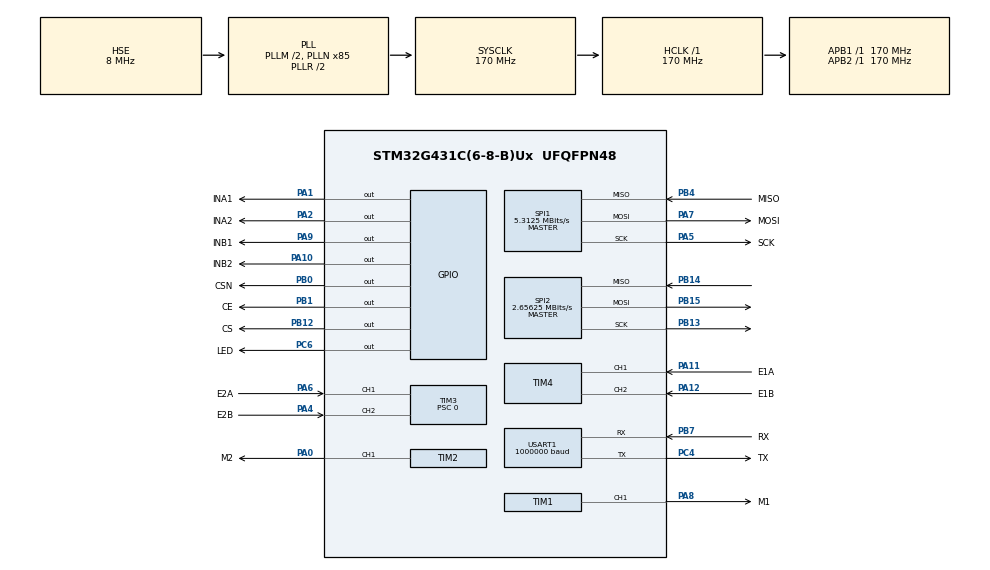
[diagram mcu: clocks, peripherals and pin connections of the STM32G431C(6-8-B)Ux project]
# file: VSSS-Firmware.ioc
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Mcu.Family=STM32G4
Mcu.Name=STM32G431C(6-8-B)Ux
Mcu.Package=UFQFPN48
NVIC.PriorityGroup=NVIC_PRIORITYGROUP_4
PA0.GPIO_Label=M2
PA0.Signal=S_TIM2_CH1
PA1.GPIO_Label=INA1
PA1.Signal=GPIO_Output
PA10.GPIO_Label=INB2
PA10.Signal=GPIO_Output
PA11.GPIO_Label=E1A
PA11.Signal=S_TIM4_CH1
PA12.GPIO_Label=E1B
PA12.Signal=S_TIM4_CH2
PA2.GPIO_Label=INA2
PA2.Signal=GPIO_Output
PA4.GPIO_Label=E2B
PA4.Signal=S_TIM3_CH2
PA5.GPIO_Label=SCK
PA5.Mode=Full_Duplex_Master
PA5.Signal=SPI1_SCK
PA6.GPIO_Label=E2A
PA6.Signal=S_TIM3_CH1
PA7.GPIO_Label=MOSI
PA7.Mode=Full_Duplex_Master
PA7.Signal=SPI1_MOSI
PA8.GPIO_Label=M1
PA8.GPIO_Speed=GPIO_SPEED_FREQ_HIGH
PA8.Signal=S_TIM1_CH1
PA9.GPIO_Label=INB1
PA9.Signal=GPIO_Output
PB0.GPIO_Label=CSN
PB0.Signal=GPIO_Output
PB1.GPIO_Label=CE
PB1.Signal=GPIO_Output
PB12.GPIO_Label=CS
PB12.Signal=GPIO_Output
PB13.Mode=Full_Duplex_Master
PB13.Signal=SPI2_SCK
PB14.Mode=Full_Duplex_Master
PB14.Signal=SPI2_MISO
PB15.Mode=Full_Duplex_Master
PB15.Signal=SPI2_MOSI
PB4.GPIO_Label=MISO
PB4.Mode=Full_Duplex_Master
PB4.Signal=SPI1_MISO
PB7.GPIO_Label=RX
PB7.Mode=Asynchronous
PB7.Signal=USART1_RX
PC4.GPIO_Label=TX
PC4.Mode=Asynchronous
PC4.Signal=USART1_TX
PC6.GPIO_Label=LED
PC6.Signal=GPIO_Output
PF0-OSC_IN.Mode=HSE-External-Oscillator
PF0-OSC_IN.Signal=RCC_OSC_IN
PF1-OSC_OUT.Mode=HSE-External-Oscillator
PF1-OSC_OUT.Signal=RCC_OSC_OUT
ProjectManager.HeapSize=0x200
ProjectManager.StackSize=0x400
ProjectManager.TargetToolchain=STM32CubeIDE
RCC.ADC12Freq_Value=170000000
RCC.AHBFreq_Value=170000000
RCC.APB1Freq_Value=170000000
RCC.APB1TimFreq_Value=170000000
RCC.APB2Freq_Value=170000000
RCC.APB2TimFreq_Value=170000000
RCC.CortexFreq_Value=170000000
RCC.EXTERNAL_CLOCK_VALUE=12288000
RCC.HCLKFreq_Value=170000000
RCC.HSE_VALUE=8000000
RCC.HSI48_VALUE=48000000
RCC.HSI_VALUE=16000000
RCC.LSE_VALUE=32768
RCC.PLLM=RCC_PLLM_DIV2
RCC.PLLN=85
RCC.PLLSourceVirtual=RCC_PLLSOURCE_HSE
RCC.SYSCLKFreq_VALUE=170000000
RCC.SYSCLKSource=RCC_SYSCLKSOURCE_PLLCLK
RCC.USBFreq_Value=170000000
RCC.VCOOutputFreq_Value=340000000
SH.S_TIM1_CH1.0=TIM1_CH1,PWM Generation1 CH1
SH.S_TIM2_CH1.0=TIM2_CH1,PWM Generation1 CH1
SH.S_TIM3_CH1.0=TIM3_CH1,Encoder_Interface
SH.S_TIM3_CH2.0=TIM3_CH2,Encoder_Interface
SH.S_TIM4_CH1.0=TIM4_CH1,Encoder_Interface
SH.S_TIM4_CH2.0=TIM4_CH2,Encoder_Interface
SPI1.BaudRatePrescaler=SPI_BAUDRATEPRESCALER_32
SPI1.CalculateBaudRate=5.3125 MBits/s
SPI1.DataSize=SPI_DATASIZE_8BIT
SPI1.Direction=SPI_DIRECTION_2LINES
SPI1.Mode=SPI_MODE_MASTER
SPI1.VirtualType=VM_MASTER
SPI2.BaudRatePrescaler=SPI_BAUDRATEPRESCALER_64
SPI2.CLKPhase=SPI_PHASE_2EDGE
SPI2.CLKPolarity=SPI_POLARITY_HIGH
SPI2.CalculateBaudRate=2.65625 MBits/s
SPI2.DataSize=SPI_DATASIZE_8BIT
SPI2.Direction=SPI_DIRECTION_2LINES
SPI2.Mode=SPI_MODE_MASTER
SPI2.VirtualType=VM_MASTER
TIM1.Channel-PWM\ Generation1\ CH1=TIM_CHANNEL_1
TIM1.PeriodNoDither=1699
TIM2.Channel-PWM\ Generation1\ CH1=TIM_CHANNEL_1
TIM2.PeriodNoDither=1699
TIM3.AutoReloadPreload=TIM_AUTORELOAD_PRELOAD_DISABLE
TIM3.CounterMode=TIM_COUNTERMODE_UP
TIM3.EncoderMode=TIM_ENCODERMODE_TI12
TIM3.IC1Filter=8
TIM3.IC1Polarity=TIM_ICPOLARITY_RISING
TIM3.IC2Filter=0
TIM3.IC2Polarity=TIM_ICPOLARITY_RISING
TIM3.Prescaler=0
TIM4.CounterMode=TIM_COUNTERMODE_UP
TIM4.Dithering=Disable
TIM4.EncoderMode=TIM_ENCODERMODE_TI12
TIM4.IC1Filter=8
TIM4.IC1Polarity=TIM_ICPOLARITY_RISING
TIM4.IC2Filter=0
TIM4.IC2Polarity=TIM_ICPOLARITY_RISING
USART1.BaudRate=1000000
USART1.VirtualMode-Asynchronous=VM_ASYNC
VP_SYS_VS_DBSignals.Mode=DisableDeadBatterySignals
VP_TIM1_VS_ClockSourceINT.Mode=Internal
VP_TIM2_VS_ClockSourceINT.Mode=Internal
board=custom

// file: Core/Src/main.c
/* USER CODE BEGIN Header */
/**
  ******************************************************************************
  * @file           : main.c
  * @brief          : Exemplo de controle PID com Anti-Windup para 2 motores
  ******************************************************************************
  * @attention
  *
  * Copyright (c) 2025.
  * Todos os direitos reservados.
  *
  * Este exemplo é fornecido "como está" (AS IS). Ajustes de hardware,
  * pinos, timers, ganhos PID e etc. podem ser necessários conforme seu projeto.
  *
  ******************************************************************************
  */
/* USER CODE END Header */
#include "main.h"

/* USER CODE BEGIN Includes */

#include "VSSS.h"

/* USER CODE END Includes */

/* USER CODE BEGIN PM */
// Macros adicionais, se desejar
/* USER CODE END PM */

SPI_HandleTypeDef hspi1;
SPI_HandleTypeDef hspi2;

TIM_HandleTypeDef htim1;
TIM_HandleTypeDef htim2;
TIM_HandleTypeDef htim3;
TIM_HandleTypeDef htim4;

UART_HandleTypeDef huart1;

void SystemClock_Config(void);
static void MX_GPIO_Init(void);
static void MX_TIM1_Init(void);
static void MX_TIM2_Init(void);
static void MX_TIM3_Init(void);
static void MX_TIM4_Init(void);
static void MX_SPI1_Init(void);
static void MX_USART1_UART_Init(void);
static void MX_SPI2_Init(void);
/* USER CODE BEGIN PFP */
void HAL_GPIO_EXTI_Callback(uint16_t GPIO_Pin);

/* USER CODE END PFP */

int main(void)
{

  /* MCU Configuration--------------------------------------------------------*/

  /* Reset of all peripherals, Initializes the Flash interface and the Systick. */
  HAL_Init();

  /* Configure the system clock */
  SystemClock_Config();

  /* Initialize all configured peripherals */
  MX_GPIO_Init();
  MX_TIM1_Init();
  MX_TIM2_Init();
  MX_TIM3_Init();
  MX_TIM4_Init();
  MX_SPI1_Init();
  MX_USART1_UART_Init();
  MX_SPI2_Init();
  /* USER CODE BEGIN 2 */
  VSSS_Init();

  /* USER CODE END 2 */

  /* Infinite loop */
  /* USER CODE BEGIN WHILE */
  while (1)
  {
	  VSSS_Run();
  }
    /* USER CODE END WHILE */

}

void SystemClock_Config(void)
{
  RCC_OscInitTypeDef RCC_OscInitStruct = {0};
  RCC_ClkInitTypeDef RCC_ClkInitStruct = {0};

  /** Configure the main internal regulator output voltage
  */
  HAL_PWREx_ControlVoltageScaling(PWR_REGULATOR_VOLTAGE_SCALE1_BOOST);

  /** Initializes the RCC Oscillators according to the specified parameters
  * in the RCC_OscInitTypeDef structure.
  */
  RCC_OscInitStruct.OscillatorType = RCC_OSCILLATORTYPE_HSE;
  RCC_OscInitStruct.HSEState = RCC_HSE_ON;
  RCC_OscInitStruct.PLL.PLLState = RCC_PLL_ON;
  RCC_OscInitStruct.PLL.PLLSource = RCC_PLLSOURCE_HSE;
  RCC_OscInitStruct.PLL.PLLM = RCC_PLLM_DIV2;
  RCC_OscInitStruct.PLL.PLLN = 85;
  RCC_OscInitStruct.PLL.PLLP = RCC_PLLP_DIV2;
  RCC_OscInitStruct.PLL.PLLQ = RCC_PLLQ_DIV2;
  RCC_OscInitStruct.PLL.PLLR = RCC_PLLR_DIV2;
  if (HAL_RCC_OscConfig(&RCC_OscInitStruct) != HAL_OK)
  {
    Error_Handler();
  }

  /** Initializes the CPU, AHB and APB buses clocks
  */
  RCC_ClkInitStruct.ClockType = RCC_CLOCKTYPE_HCLK|RCC_CLOCKTYPE_SYSCLK
                              |RCC_CLOCKTYPE_PCLK1|RCC_CLOCKTYPE_PCLK2;
  RCC_ClkInitStruct.SYSCLKSource = RCC_SYSCLKSOURCE_PLLCLK;
  RCC_ClkInitStruct.AHBCLKDivider = RCC_SYSCLK_DIV1;
  RCC_ClkInitStruct.APB1CLKDivider = RCC_HCLK_DIV1;
  RCC_ClkInitStruct.APB2CLKDivider = RCC_HCLK_DIV1;

  if (HAL_RCC_ClockConfig(&RCC_ClkInitStruct, FLASH_LATENCY_4) != HAL_OK)
  {
    Error_Handler();
  }
}

static void MX_SPI1_Init(void)
{

  /* SPI1 parameter configuration*/
  hspi1.Instance = SPI1;
  hspi1.Init.Mode = SPI_MODE_MASTER;
  hspi1.Init.Direction = SPI_DIRECTION_2LINES;
  hspi1.Init.DataSize = SPI_DATASIZE_8BIT;
  hspi1.Init.CLKPolarity = SPI_POLARITY_LOW;
  hspi1.Init.CLKPhase = SPI_PHASE_1EDGE;
  hspi1.Init.NSS = SPI_NSS_SOFT;
  hspi1.Init.BaudRatePrescaler = SPI_BAUDRATEPRESCALER_32;
  hspi1.Init.FirstBit = SPI_FIRSTBIT_MSB;
  hspi1.Init.TIMode = SPI_TIMODE_DISABLE;
  hspi1.Init.CRCCalculation = SPI_CRCCALCULATION_DISABLE;
  hspi1.Init.CRCPolynomial = 7;
  hspi1.Init.CRCLength = SPI_CRC_LENGTH_DATASIZE;
  hspi1.Init.NSSPMode = SPI_NSS_PULSE_ENABLE;
  if (HAL_SPI_Init(&hspi1) != HAL_OK)
  {
    Error_Handler();
  }

}

static void MX_SPI2_Init(void)
{

  /* SPI2 parameter configuration*/
  hspi2.Instance = SPI2;
  hspi2.Init.Mode = SPI_MODE_MASTER;
  hspi2.Init.Direction = SPI_DIRECTION_2LINES;
  hspi2.Init.DataSize = SPI_DATASIZE_8BIT;
  hspi2.Init.CLKPolarity = SPI_POLARITY_HIGH;
  hspi2.Init.CLKPhase = SPI_PHASE_2EDGE;
  hspi2.Init.NSS = SPI_NSS_SOFT;
  hspi2.Init.BaudRatePrescaler = SPI_BAUDRATEPRESCALER_64;
  hspi2.Init.FirstBit = SPI_FIRSTBIT_MSB;
  hspi2.Init.TIMode = SPI_TIMODE_DISABLE;
  hspi2.Init.CRCCalculation = SPI_CRCCALCULATION_DISABLE;
  hspi2.Init.CRCPolynomial = 7;
  hspi2.Init.CRCLength = SPI_CRC_LENGTH_DATASIZE;
  hspi2.Init.NSSPMode = SPI_NSS_PULSE_DISABLE;
  if (HAL_SPI_Init(&hspi2) != HAL_OK)
  {
    Error_Handler();
  }

}

static void MX_TIM1_Init(void)
{

  TIM_ClockConfigTypeDef sClockSourceConfig = {0};
  TIM_MasterConfigTypeDef sMasterConfig = {0};
  TIM_OC_InitTypeDef sConfigOC = {0};
  TIM_BreakDeadTimeConfigTypeDef sBreakDeadTimeConfig = {0};

  htim1.Instance = TIM1;
  htim1.Init.Prescaler = 0;
  htim1.Init.CounterMode = TIM_COUNTERMODE_UP;
  htim1.Init.Period = 1699;
  htim1.Init.ClockDivision = TIM_CLOCKDIVISION_DIV1;
  htim1.Init.RepetitionCounter = 0;
  htim1.Init.AutoReloadPreload = TIM_AUTORELOAD_PRELOAD_DISABLE;
  if (HAL_TIM_Base_Init(&htim1) != HAL_OK)
  {
    Error_Handler();
  }
  sClockSourceConfig.ClockSource = TIM_CLOCKSOURCE_INTERNAL;
  if (HAL_TIM_ConfigClockSource(&htim1, &sClockSourceConfig) != HAL_OK)
  {
    Error_Handler();
  }
  if (HAL_TIM_PWM_Init(&htim1) != HAL_OK)
  {
    Error_Handler();
  }
  sMasterConfig.MasterOutputTrigger = TIM_TRGO_RESET;
  sMasterConfig.MasterOutputTrigger2 = TIM_TRGO2_RESET;
  sMasterConfig.MasterSlaveMode = TIM_MASTERSLAVEMODE_DISABLE;
  if (HAL_TIMEx_MasterConfigSynchronization(&htim1, &sMasterConfig) != HAL_OK)
  {
    Error_Handler();
  }
  sConfigOC.OCMode = TIM_OCMODE_PWM1;
  sConfigOC.Pulse = 0;
  sConfigOC.OCPolarity = TIM_OCPOLARITY_HIGH;
  sConfigOC.OCNPolarity = TIM_OCNPOLARITY_HIGH;
  sConfigOC.OCFastMode = TIM_OCFAST_DISABLE;
  sConfigOC.OCIdleState = TIM_OCIDLESTATE_RESET;
  sConfigOC.OCNIdleState = TIM_OCNIDLESTATE_RESET;
  if (HAL_TIM_PWM_ConfigChannel(&htim1, &sConfigOC, TIM_CHANNEL_1) != HAL_OK)
  {
    Error_Handler();
  }
  sBreakDeadTimeConfig.OffStateRunMode = TIM_OSSR_DISABLE;
  sBreakDeadTimeConfig.OffStateIDLEMode = TIM_OSSI_DISABLE;
  sBreakDeadTimeConfig.LockLevel = TIM_LOCKLEVEL_OFF;
  sBreakDeadTimeConfig.DeadTime = 0;
  sBreakDeadTimeConfig.BreakState = TIM_BREAK_DISABLE;
  sBreakDeadTimeConfig.BreakPolarity = TIM_BREAKPOLARITY_HIGH;
  sBreakDeadTimeConfig.BreakFilter = 0;
  sBreakDeadTimeConfig.BreakAFMode = TIM_BREAK_AFMODE_INPUT;
  sBreakDeadTimeConfig.Break2State = TIM_BREAK2_DISABLE;
  sBreakDeadTimeConfig.Break2Polarity = TIM_BREAK2POLARITY_HIGH;
  sBreakDeadTimeConfig.Break2Filter = 0;
  sBreakDeadTimeConfig.Break2AFMode = TIM_BREAK_AFMODE_INPUT;
  sBreakDeadTimeConfig.AutomaticOutput = TIM_AUTOMATICOUTPUT_DISABLE;
  if (HAL_TIMEx_ConfigBreakDeadTime(&htim1, &sBreakDeadTimeConfig) != HAL_OK)
  {
    Error_Handler();
  }
  HAL_TIM_MspPostInit(&htim1);

}

static void MX_TIM2_Init(void)
{

  TIM_ClockConfigTypeDef sClockSourceConfig = {0};
  TIM_MasterConfigTypeDef sMasterConfig = {0};
  TIM_OC_InitTypeDef sConfigOC = {0};

  htim2.Instance = TIM2;
  htim2.Init.Prescaler = 0;
  htim2.Init.CounterMode = TIM_COUNTERMODE_UP;
  htim2.Init.Period = 1699;
  htim2.Init.ClockDivision = TIM_CLOCKDIVISION_DIV1;
  htim2.Init.AutoReloadPreload = TIM_AUTORELOAD_PRELOAD_DISABLE;
  if (HAL_TIM_Base_Init(&htim2) != HAL_OK)
  {
    Error_Handler();
  }
  sClockSourceConfig.ClockSource = TIM_CLOCKSOURCE_INTERNAL;
  if (HAL_TIM_ConfigClockSource(&htim2, &sClockSourceConfig) != HAL_OK)
  {
    Error_Handler();
  }
  if (HAL_TIM_PWM_Init(&htim2) != HAL_OK)
  {
    Error_Handler();
  }
  sMasterConfig.MasterOutputTrigger = TIM_TRGO_RESET;
  sMasterConfig.MasterSlaveMode = TIM_MASTERSLAVEMODE_DISABLE;
  if (HAL_TIMEx_MasterConfigSynchronization(&htim2, &sMasterConfig) != HAL_OK)
  {
    Error_Handler();
  }
  sConfigOC.OCMode = TIM_OCMODE_PWM1;
  sConfigOC.Pulse = 0;
  sConfigOC.OCPolarity = TIM_OCPOLARITY_HIGH;
  sConfigOC.OCFastMode = TIM_OCFAST_DISABLE;
  if (HAL_TIM_PWM_ConfigChannel(&htim2, &sConfigOC, TIM_CHANNEL_1) != HAL_OK)
  {
    Error_Handler();
  }
  HAL_TIM_MspPostInit(&htim2);

}

static void MX_TIM3_Init(void)
{

  TIM_Encoder_InitTypeDef sConfig = {0};
  TIM_MasterConfigTypeDef sMasterConfig = {0};

  htim3.Instance = TIM3;
  htim3.Init.Prescaler = 0;
  htim3.Init.CounterMode = TIM_COUNTERMODE_UP;
  htim3.Init.Period = 65535;
  htim3.Init.ClockDivision = TIM_CLOCKDIVISION_DIV1;
  htim3.Init.AutoReloadPreload = TIM_AUTORELOAD_PRELOAD_DISABLE;
  sConfig.EncoderMode = TIM_ENCODERMODE_TI12;
  sConfig.IC1Polarity = TIM_ICPOLARITY_RISING;
  sConfig.IC1Selection = TIM_ICSELECTION_DIRECTTI;
  sConfig.IC1Prescaler = TIM_ICPSC_DIV1;
  sConfig.IC1Filter = 8;
  sConfig.IC2Polarity = TIM_ICPOLARITY_RISING;
  sConfig.IC2Selection = TIM_ICSELECTION_DIRECTTI;
  sConfig.IC2Prescaler = TIM_ICPSC_DIV1;
  sConfig.IC2Filter = 0;
  if (HAL_TIM_Encoder_Init(&htim3, &sConfig) != HAL_OK)
  {
    Error_Handler();
  }
  sMasterConfig.MasterOutputTrigger = TIM_TRGO_RESET;
  sMasterConfig.MasterSlaveMode = TIM_MASTERSLAVEMODE_DISABLE;
  if (HAL_TIMEx_MasterConfigSynchronization(&htim3, &sMasterConfig) != HAL_OK)
  {
    Error_Handler();
  }

}

static void MX_TIM4_Init(void)
{

  TIM_Encoder_InitTypeDef sConfig = {0};
  TIM_MasterConfigTypeDef sMasterConfig = {0};

  htim4.Instance = TIM4;
  htim4.Init.Prescaler = 0;
  htim4.Init.CounterMode = TIM_COUNTERMODE_UP;
  htim4.Init.Period = 65535;
  htim4.Init.ClockDivision = TIM_CLOCKDIVISION_DIV1;
  htim4.Init.AutoReloadPreload = TIM_AUTORELOAD_PRELOAD_DISABLE;
  sConfig.EncoderMode = TIM_ENCODERMODE_TI12;
  sConfig.IC1Polarity = TIM_ICPOLARITY_RISING;
  sConfig.IC1Selection = TIM_ICSELECTION_DIRECTTI;
  sConfig.IC1Prescaler = TIM_ICPSC_DIV1;
  sConfig.IC1Filter = 8;
  sConfig.IC2Polarity = TIM_ICPOLARITY_RISING;
  sConfig.IC2Selection = TIM_ICSELECTION_DIRECTTI;
  sConfig.IC2Prescaler = TIM_ICPSC_DIV1;
  sConfig.IC2Filter = 0;
  if (HAL_TIM_Encoder_Init(&htim4, &sConfig) != HAL_OK)
  {
    Error_Handler();
  }
  sMasterConfig.MasterOutputTrigger = TIM_TRGO_RESET;
  sMasterConfig.MasterSlaveMode = TIM_MASTERSLAVEMODE_DISABLE;
  if (HAL_TIMEx_MasterConfigSynchronization(&htim4, &sMasterConfig) != HAL_OK)
  {
    Error_Handler();
  }

}

static void MX_USART1_UART_Init(void)
{

  huart1.Instance = USART1;
  huart1.Init.BaudRate = 1000000;
  huart1.Init.WordLength = UART_WORDLENGTH_8B;
  huart1.Init.StopBits = UART_STOPBITS_1;
  huart1.Init.Parity = UART_PARITY_NONE;
  huart1.Init.Mode = UART_MODE_TX_RX;
  huart1.Init.HwFlowCtl = UART_HWCONTROL_NONE;
  huart1.Init.OverSampling = UART_OVERSAMPLING_16;
  huart1.Init.OneBitSampling = UART_ONE_BIT_SAMPLE_DISABLE;
  huart1.Init.ClockPrescaler = UART_PRESCALER_DIV1;
  huart1.AdvancedInit.AdvFeatureInit = UART_ADVFEATURE_NO_INIT;
  if (HAL_UART_Init(&huart1) != HAL_OK)
  {
    Error_Handler();
  }
  if (HAL_UARTEx_SetTxFifoThreshold(&huart1, UART_TXFIFO_THRESHOLD_1_8) != HAL_OK)
  {
    Error_Handler();
  }
  if (HAL_UARTEx_SetRxFifoThreshold(&huart1, UART_RXFIFO_THRESHOLD_1_8) != HAL_OK)
  {
    Error_Handler();
  }
  if (HAL_UARTEx_DisableFifoMode(&huart1) != HAL_OK)
  {
    Error_Handler();
  }

}

static void MX_GPIO_Init(void)
{
  GPIO_InitTypeDef GPIO_InitStruct = {0};

  /* GPIO Ports Clock Enable */
  __HAL_RCC_GPIOF_CLK_ENABLE();
  __HAL_RCC_GPIOA_CLK_ENABLE();
  __HAL_RCC_GPIOC_CLK_ENABLE();
  __HAL_RCC_GPIOB_CLK_ENABLE();

  /*Configure GPIO pin Output Level */
  HAL_GPIO_WritePin(GPIOA, INA1_Pin|INA2_Pin|INB1_Pin|INB2_Pin, GPIO_PIN_RESET);

  /*Configure GPIO pin Output Level */
  HAL_GPIO_WritePin(GPIOB, CSN_Pin|CE_Pin|CS_Pin, GPIO_PIN_RESET);

  /*Configure GPIO pin Output Level */
  HAL_GPIO_WritePin(LED_GPIO_Port, LED_Pin, GPIO_PIN_RESET);

  /*Configure GPIO pins : INA1_Pin INA2_Pin INB1_Pin INB2_Pin */
  GPIO_InitStruct.Pin = INA1_Pin|INA2_Pin|INB1_Pin|INB2_Pin;
  GPIO_InitStruct.Mode = GPIO_MODE_OUTPUT_PP;
  GPIO_InitStruct.Pull = GPIO_NOPULL;
  GPIO_InitStruct.Speed = GPIO_SPEED_FREQ_LOW;
  HAL_GPIO_Init(GPIOA, &GPIO_InitStruct);

  /*Configure GPIO pins : CSN_Pin CE_Pin CS_Pin */
  GPIO_InitStruct.Pin = CSN_Pin|CE_Pin|CS_Pin;
  GPIO_InitStruct.Mode = GPIO_MODE_OUTPUT_PP;
  GPIO_InitStruct.Pull = GPIO_NOPULL;
  GPIO_InitStruct.Speed = GPIO_SPEED_FREQ_LOW;
  HAL_GPIO_Init(GPIOB, &GPIO_InitStruct);

  /*Configure GPIO pin : LED_Pin */
  GPIO_InitStruct.Pin = LED_Pin;
  GPIO_InitStruct.Mode = GPIO_MODE_OUTPUT_PP;
  GPIO_InitStruct.Pull = GPIO_NOPULL;
  GPIO_InitStruct.Speed = GPIO_SPEED_FREQ_LOW;
  HAL_GPIO_Init(LED_GPIO_Port, &GPIO_InitStruct);

}

void Error_Handler(void)
{
  __disable_irq();
  while (1)
  {
  }
}
